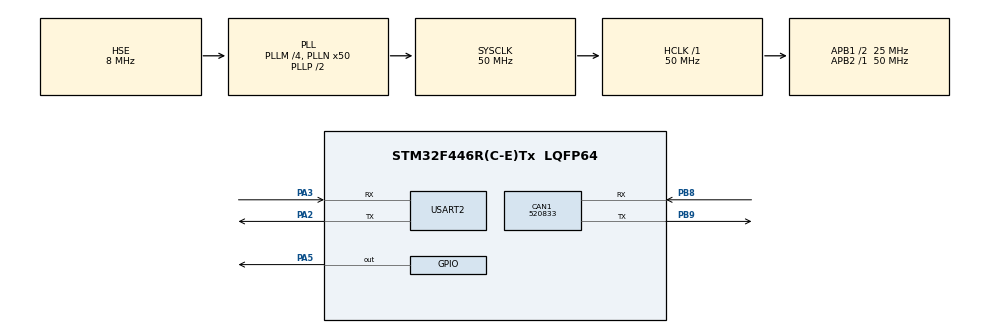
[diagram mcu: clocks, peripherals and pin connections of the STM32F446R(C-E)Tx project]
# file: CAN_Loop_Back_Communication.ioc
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CAN1.ABOM=ENABLE
CAN1.CalculateBaudRate=520833
CAN1.CalculateTimeBit=1920
CAN1.CalculateTimeQuantum=640.0
CAN1.Mode=CAN_MODE_LOOPBACK
CAN1.NART=ENABLE
Mcu.Family=STM32F4
Mcu.Name=STM32F446R(C-E)Tx
Mcu.Package=LQFP64
NVIC.CAN1_RX0_IRQn=true\:0\:0\:false\:false\:true\:true\:true\:true
NVIC.CAN1_RX1_IRQn=true\:0\:0\:false\:false\:true\:true\:true\:true
NVIC.CAN1_SCE_IRQn=true\:0\:0\:false\:false\:true\:true\:true\:true
NVIC.CAN1_TX_IRQn=true\:0\:0\:false\:false\:true\:true\:true\:true
NVIC.PriorityGroup=NVIC_PRIORITYGROUP_0
PA2.Mode=Asynchronous
PA2.Signal=USART2_TX
PA3.Mode=Asynchronous
PA3.Signal=USART2_RX
PA5.Signal=GPIO_Output
PB8.Mode=CAN_Activate
PB8.Signal=CAN1_RX
PB9.Mode=CAN_Activate
PB9.Signal=CAN1_TX
ProjectManager.HeapSize=0x200
ProjectManager.StackSize=0x400
ProjectManager.TargetToolchain=STM32CubeIDE
RCC.AHBFreq_Value=50000000
RCC.APB1CLKDivider=RCC_HCLK_DIV2
RCC.APB1Freq_Value=25000000
RCC.APB1TimFreq_Value=50000000
RCC.APB2Freq_Value=50000000
RCC.APB2TimFreq_Value=50000000
RCC.CortexFreq_Value=50000000
RCC.FLatency-AdvancedSettings=FLASH_LATENCY_1
RCC.HCLKFreq_Value=50000000
RCC.HSE_VALUE=8000000
RCC.HSI_VALUE=16000000
RCC.LSE_VALUE=32768
RCC.PLLM=8
RCC.PLLN=50
RCC.SYSCLKFreq_VALUE=50000000
RCC.SYSCLKSource=RCC_SYSCLKSOURCE_PLLCLK
RCC.USBFreq_Value=50000000
RCC.VCOOutputFreq_Value=100000000
USART2.VirtualMode=VM_ASYNC
board=NUCLEO-F446RE

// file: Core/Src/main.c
/* USER CODE BEGIN Header */
/**
  ******************************************************************************
  * @file           : main.c
  * @brief          : Main program body
  ******************************************************************************
  * @attention
  *
  * Copyright (c) 2024 STMicroelectronics.
  * All rights reserved.
  *
  * This software is licensed under terms that can be found in the LICENSE file
  * in the root directory of this software component.
  * If no LICENSE file comes with this software, it is provided AS-IS.
  *
  ******************************************************************************
  */
/* USER CODE END Header */
#include "main.h"

CAN_HandleTypeDef hcan1;

UART_HandleTypeDef huart2;

void SystemClock_Config(void);
static void MX_GPIO_Init(void);
static void MX_CAN1_Init(void);
static void MX_USART2_UART_Init(void);
void CAN1_Tx(void);
void CAN1_Rx(void);
void CAN_Filter_Config(void);

int main(void)
{

  /* MCU Configuration--------------------------------------------------------*/

  /* Reset of all peripherals, Initializes the Flash interface and the Systick. */
  HAL_Init();

  /* Configure the system clock */
  SystemClock_Config();

  /* Initialize all configured peripherals */
  MX_GPIO_Init();
  MX_CAN1_Init();
  MX_USART2_UART_Init();
  /* USER CODE BEGIN 2 */

  //Configure the filter acceptance
  CAN_Filter_Config();

  //Move the can controller to the normal mode
  HAL_CAN_Start(&hcan1);

  //Transmit some data over CAN
  CAN1_Tx();

  //Receive some data over CAN
  CAN1_Rx();

  /* USER CODE END 2 */

  /* Infinite loop */
  while (1)
  {

  }
}

void SystemClock_Config(void)
{
  RCC_OscInitTypeDef RCC_OscInitStruct = {0};
  RCC_ClkInitTypeDef RCC_ClkInitStruct = {0};

  /** Configure the main internal regulator output voltage
  */
  __HAL_RCC_PWR_CLK_ENABLE();
  __HAL_PWR_VOLTAGESCALING_CONFIG(PWR_REGULATOR_VOLTAGE_SCALE3);

  /** Initializes the RCC Oscillators according to the specified parameters
  * in the RCC_OscInitTypeDef structure.
  */
  RCC_OscInitStruct.OscillatorType = RCC_OSCILLATORTYPE_HSE;
  RCC_OscInitStruct.HSEState = RCC_HSE_ON;
  RCC_OscInitStruct.PLL.PLLState = RCC_PLL_ON;
  RCC_OscInitStruct.PLL.PLLSource = RCC_PLLSOURCE_HSE;
  RCC_OscInitStruct.PLL.PLLM = 4;
  RCC_OscInitStruct.PLL.PLLN = 50;
  RCC_OscInitStruct.PLL.PLLP = RCC_PLLP_DIV2;
  RCC_OscInitStruct.PLL.PLLQ = 2;
  RCC_OscInitStruct.PLL.PLLR = 2;
  if (HAL_RCC_OscConfig(&RCC_OscInitStruct) != HAL_OK)
  {
    Error_Handler();
  }

  /** Initializes the CPU, AHB and APB buses clocks
  */
  RCC_ClkInitStruct.ClockType = RCC_CLOCKTYPE_HCLK|RCC_CLOCKTYPE_SYSCLK
                              |RCC_CLOCKTYPE_PCLK1|RCC_CLOCKTYPE_PCLK2;
  RCC_ClkInitStruct.SYSCLKSource = RCC_SYSCLKSOURCE_PLLCLK;
  RCC_ClkInitStruct.AHBCLKDivider = RCC_SYSCLK_DIV1;
  RCC_ClkInitStruct.APB1CLKDivider = RCC_HCLK_DIV2;
  RCC_ClkInitStruct.APB2CLKDivider = RCC_HCLK_DIV1;

  if (HAL_RCC_ClockConfig(&RCC_ClkInitStruct, FLASH_LATENCY_1) != HAL_OK)
  {
    Error_Handler();
  }
}

static void MX_CAN1_Init(void)
{

  hcan1.Instance = CAN1;
  hcan1.Init.Prescaler = 5;
  hcan1.Init.Mode = CAN_MODE_LOOPBACK;
  hcan1.Init.SyncJumpWidth = CAN_SJW_1TQ;
  hcan1.Init.TimeSeg1 = CAN_BS1_8TQ;
  hcan1.Init.TimeSeg2 = CAN_BS2_1TQ;
  hcan1.Init.TimeTriggeredMode = DISABLE;
  hcan1.Init.AutoBusOff = ENABLE;
  hcan1.Init.AutoWakeUp = DISABLE;
  hcan1.Init.AutoRetransmission = ENABLE;
  hcan1.Init.ReceiveFifoLocked = DISABLE;
  hcan1.Init.TransmitFifoPriority = DISABLE;
  if (HAL_CAN_Init(&hcan1) != HAL_OK)
  {
    Error_Handler();
  }

}

void CAN1_Rx(void) {
	//Handle structure to store RxHeader information.
	CAN_RxHeaderTypeDef RxHeader;

	//buffer to store the data received over can
	uint8_t Rcv_msg[5];

	//buffer to send the data received on the can network over uart.
	char uart_msg[50];

	//wait until at least one message get received on the fifo zero.
	while(! HAL_CAN_GetRxFifoFillLevel(&hcan1, CAN_RX_FIFO0));

	if (HAL_CAN_GetRxMessage(&hcan1, CAN_RX_FIFO0, &RxHeader, Rcv_msg) != HAL_OK) {
		Error_Handler();
	}

	sprintf(uart_msg,"Message received : %s\r\n",Rcv_msg);
	HAL_UART_Transmit(&huart2, Rcv_msg, sizeof(Rcv_msg), HAL_MAX_DELAY);
}

/**
  * @brief CAN transmission function
  * @param None
  * @retval None
  */
void CAN1_Tx(void) {
	CAN_TxHeaderTypeDef Txheader;
	uint8_t uartMsg[] = "Message transmitted!\r\n";
	uint8_t message[5] = {'H','E','L','L','O'};
	uint32_t TxMailBox;
	Txheader.DLC = 5;
	Txheader.StdId = 0x65D;
	Txheader.IDE = CAN_ID_STD;
	Txheader.RTR = CAN_RTR_DATA;
	if (HAL_CAN_AddTxMessage(&hcan1, &Txheader, message, &TxMailBox) != HAL_OK) {
		Error_Handler();
	}
	while(HAL_CAN_IsTxMessagePending(&hcan1, TxMailBox));
	HAL_UART_Transmit(&huart2, uartMsg, sizeof(uartMsg), HAL_MAX_DELAY);
}

/**
  * @brief CAN filter config function
  * @param None
  * @retval None
  */
void CAN_Filter_Config(void) {
	CAN_FilterTypeDef can_filter;

	can_filter.FilterActivation = ENABLE;
	can_filter.FilterBank = 0;
	can_filter.FilterFIFOAssignment = CAN_FILTER_FIFO0;
	can_filter.FilterIdHigh = 0x00000000;
	can_filter.FilterIdLow = 0x00000000;
	can_filter.FilterMaskIdHigh = 0x00000000;
	can_filter.FilterMaskIdLow = 0x00000000;
	can_filter.FilterMode = CAN_FILTERMODE_IDMASK;
	can_filter.FilterScale = CAN_FILTERSCALE_32BIT;

	if (HAL_CAN_ConfigFilter(&hcan1, & can_filter) != HAL_OK) {
		Error_Handler();
	}
}

static void MX_USART2_UART_Init(void)
{

  huart2.Instance = USART2;
  huart2.Init.BaudRate = 115200;
  huart2.Init.WordLength = UART_WORDLENGTH_8B;
  huart2.Init.StopBits = UART_STOPBITS_1;
  huart2.Init.Parity = UART_PARITY_NONE;
  huart2.Init.Mode = UART_MODE_TX_RX;
  huart2.Init.HwFlowCtl = UART_HWCONTROL_NONE;
  huart2.Init.OverSampling = UART_OVERSAMPLING_16;
  if (HAL_UART_Init(&huart2) != HAL_OK)
  {
    Error_Handler();
  }

}

static void MX_GPIO_Init(void)
{
  GPIO_InitTypeDef GPIO_InitStruct = {0};

  /* GPIO Ports Clock Enable */
  __HAL_RCC_GPIOA_CLK_ENABLE();
  __HAL_RCC_GPIOB_CLK_ENABLE();

  /*Configure GPIO pin Output Level */
  HAL_GPIO_WritePin(GPIOA, GPIO_PIN_5, GPIO_PIN_RESET);

  /*Configure GPIO pin : PA5 */
  GPIO_InitStruct.Pin = GPIO_PIN_5;
  GPIO_InitStruct.Mode = GPIO_MODE_OUTPUT_PP;
  GPIO_InitStruct.Pull = GPIO_NOPULL;
  GPIO_InitStruct.Speed = GPIO_SPEED_FREQ_LOW;
  HAL_GPIO_Init(GPIOA, &GPIO_InitStruct);

}

void Error_Handler(void)
{
  __disable_irq();
  while (1)
  {
  }
}
